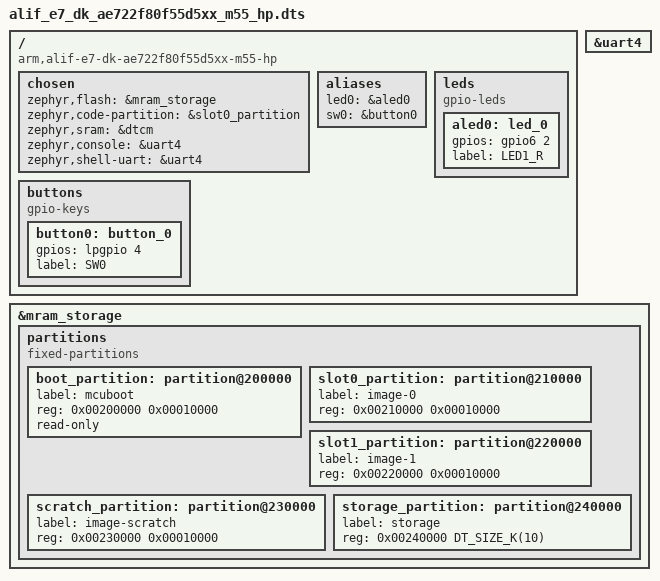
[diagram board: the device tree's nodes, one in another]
/* Copyright (c) 2025 Alif Semiconductor
 *
 * SPDX-License-Identifier: Apache-2.0
 */

/dts-v1/;

#include <alif/ensemble/e7/ae722f80f55d5xx_m55_hp.dtsi>
#include "../common/ensemble-pinctrl.dtsi"

/ {
	compatible = "arm,alif-e7-dk-ae722f80f55d5xx-m55-hp";
	#address-cells = <1>;
	#size-cells = <1>;

	chosen {
		zephyr,flash = &mram_storage;
		zephyr,code-partition = &slot0_partition;
		zephyr,sram = &dtcm;
		zephyr,console = &uart4;
		zephyr,shell-uart = &uart4;
	};

	aliases {
		led0 = &aled0;
		sw0 = &button0;
	};
	leds {
		compatible = "gpio-leds";
		aled0: led_0 {
			gpios = <&gpio6 2 0>;
			label = "LED1_R";
		};
	};

	buttons {
		compatible = "gpio-keys";
		button0: button_0 {
			gpios = < &lpgpio 4 0 >;
			label = "SW0";
		};
	};
};

&uart4 {
	status = "okay";
};

&mram_storage {
	partitions {
		compatible = "fixed-partitions";
		#address-cells = <1>;
		#size-cells = <1>;
		boot_partition: partition@200000 {
			label = "mcuboot";
			reg = <0x00200000 0x00010000>;
			read-only;
		};
		slot0_partition: partition@210000 {
			label = "image-0";
			reg = <0x00210000 0x00010000>;
		};
		slot1_partition: partition@220000 {
			label = "image-1";
			reg = <0x00220000 0x00010000>;
		};
		scratch_partition: partition@230000 {
			label = "image-scratch";
			reg = <0x00230000 0x00010000>;
		};
		storage_partition: partition@240000 {
			label = "storage";
			reg = <0x00240000 DT_SIZE_K(10)>;
		};
	};
};
